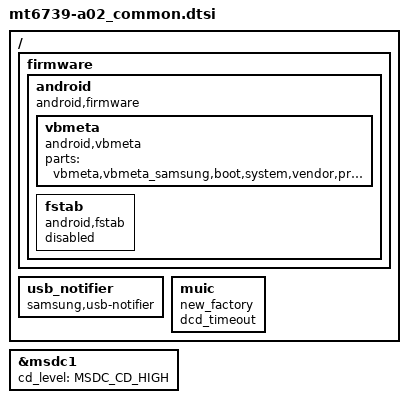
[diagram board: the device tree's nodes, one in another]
/* Generated by Samsung for MTK vendor board 
 * If these files should be changed, then please make a sync with MTK
*/

/* Add Samsung configuration over here */
/ {
	fragment@model {
		target-path = "/";
		__overlay__ {
			firmware {
					android {
							compatible = "android,firmware";
							vbmeta {
									compatible = "android,vbmeta";
									parts = "vbmeta,vbmeta_samsung,boot,system,vendor,product,odm,prism,optics,recovery,tee1,lk";
							};
							fstab {
									compatible = "android,fstab";
									status = "disabled";
							};
					};
			};
			usb_notifier {
				compatible = "samsung,usb-notifier";
			};
			muic {
				new_factory;
				dcd_timeout;
			};
		};
	};
};

/* MSDC1 */
&msdc1 {
	cd_level = /bits/ 8 <MSDC_CD_HIGH>;
};
